# STM32L562 register map
File version: 1.1
Registers are 32-bit, read-write, reset 0x0 unless marked. A register's access mark holds for its fields unless they carry their own. Offsets are from the block's base; [hi:lo] are bit positions; {n}, {i} and the like mark numbered series.

## USB — Universal serial bus full-speed device interface
Base 0x4000D400
Same registers: SEC_USB 0x5000D400
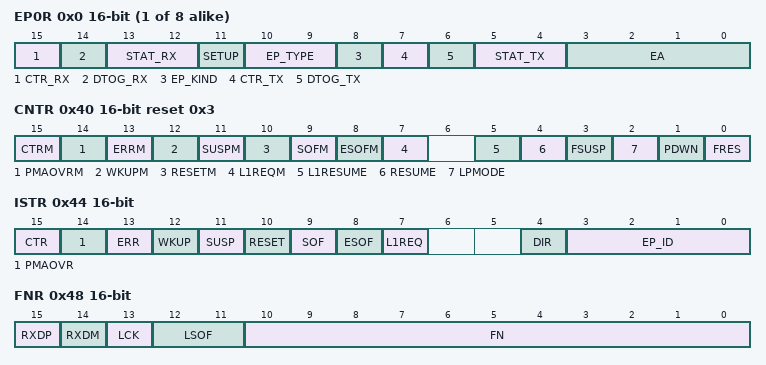
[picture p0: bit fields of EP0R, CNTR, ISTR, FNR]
{0x0+4i} EP{i}R 16-bit (i=0..7) — endpoint {i} register
  [15] CTR_RX — Correct transfer for reception
  [14] DTOG_RX — Data Toggle, for reception transfers
  [13:12] STAT_RX — Status bits, for reception transfers
  [11] SETUP — Setup transaction completed
  [10:9] EP_TYPE — Endpoint type
  [8] EP_KIND — Endpoint kind
  [7] CTR_TX — Correct Transfer for transmission
  [6] DTOG_TX — Data Toggle, for transmission transfers
  [5:4] STAT_TX — Status bits, for transmission transfers
  [3:0] EA — Endpoint address
0x40 CNTR 16-bit reset 0x3 — control register
  [15] CTRM — Correct transfer interrupt mask
  [14] PMAOVRM — Packet memory area over / underrun interrupt mask
  [13] ERRM — Error interrupt mask
  [12] WKUPM — Wakeup interrupt mask
  [11] SUSPM — Suspend mode interrupt mask
  [10] RESETM — USB reset interrupt mask
  [9] SOFM — Start of frame interrupt mask
  [8] ESOFM — Expected start of frame interrupt mask
  [7] L1REQM — LPM L1 state request interrupt mask
  [5] L1RESUME — LPM L1 Resume request
  [4] RESUME — Resume request
  [3] FSUSP — Force suspend
  [2] LPMODE — Low-power mode
  [1] PDWN — Power down
  [0] FRES — Force USB Reset
0x44 ISTR 16-bit access per field — interrupt status register
  [15] CTR ro — Correct transfer
  [14] PMAOVR rw — Packet memory area over / underrun
  [13] ERR rw — Error
  [12] WKUP rw — Wakeup
  [11] SUSP rw — Suspend mode request
  [10] RESET rw — reset request
  [9] SOF rw — start of frame
  [8] ESOF rw — Expected start frame
  [7] L1REQ rw — LPM L1 state request
  [4] DIR ro — Direction of transaction
  [3:0] EP_ID ro — Endpoint Identifier
0x48 FNR 16-bit ro — frame number register
  [15] RXDP — Receive data + line status
  [14] RXDM — Receive data - line status
  [13] LCK — Locked
  [12:11] LSOF — Lost SOF
  [10:0] FN — Frame number
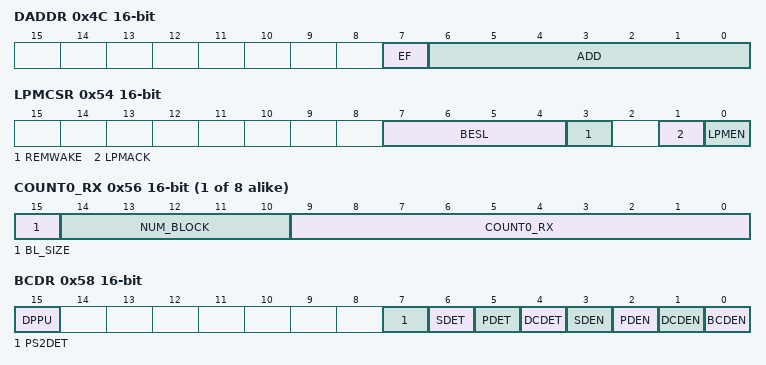
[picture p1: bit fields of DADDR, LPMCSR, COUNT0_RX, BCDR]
0x4C DADDR 16-bit — device address
  [7] EF — Enable function
  [6:0] ADD — Device address
0x50 BTABLE 16-bit — Buffer table address
  [15:3] BTABLE — Buffer table
{0x52+8i} COUNT{i}_TX 16-bit (i=0..7) — Transmission byte count 0
  [9:0] COUNT{i}_TX — Transmission byte count
0x54 LPMCSR 16-bit — LPM control and status register
  [7:4] BESL — BESL value
  [3] REMWAKE — RemoteWake value
  [1] LPMACK — LPM Token acknowledge enable
  [0] LPMEN — LPM support enable
{0x56+8i} COUNT{i}_RX 16-bit access per field (i=0..7) — Reception byte count 0
  [15] BL_SIZE rw — Block size
  [14:10] NUM_BLOCK rw — Number of blocks
  [9:0] COUNT{i}_RX ro — Reception byte count
0x58 BCDR 16-bit — Battery charging detector
  [15] DPPU — DP pull-up control
  [7] PS2DET — DM pull-up detection status
  [6] SDET — Secondary detection (SD) status
  [5] PDET — Primary detection (PD) status
  [4] DCDET — Data contact detection (DCD) status
  [3] SDEN — Secondary detection (SD) mode enable
  [2] PDEN — Primary detection (PD) mode enable
  [1] DCDEN — Data contact detection (DCD) mode enable
  [0] BCDEN — Battery charging detector (BCD) enable
{0x5C+8i} ADDR{i}_RX 16-bit (i=0..7) — Reception buffer address 0
  [15:1] ADDR{i}_RX — Reception buffer address

## LPUART1 — Universal synchronous asynchronous receiver transmitter
Base 0x40008000
Same registers: SEC_LPUART1 0x50008000
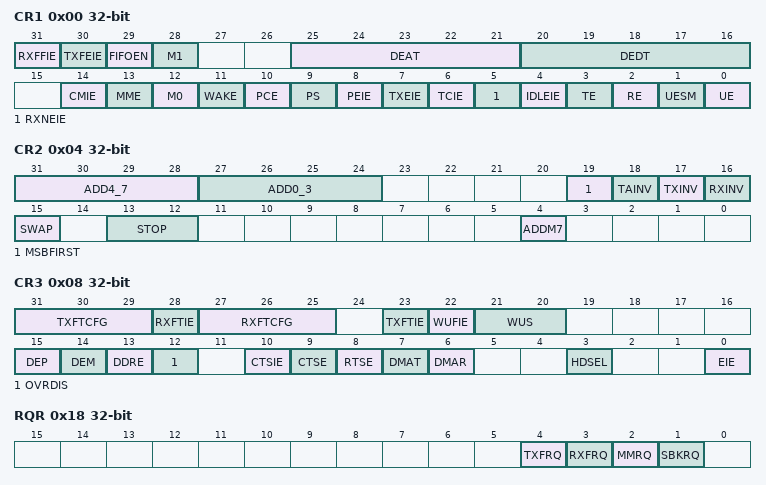
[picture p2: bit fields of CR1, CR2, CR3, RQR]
0x00 CR1 — Control register 1
  [31] RXFFIE
  [30] TXFEIE
  [29] FIFOEN
  [28] M1 — Word length
  [25:21] DEAT
  [20:16] DEDT
  [14] CMIE — Character match interrupt enable
  [13] MME — Mute mode enable
  [12] M0 — Word length
  [11] WAKE — Receiver wakeup method
  [10] PCE — Parity control enable
  [9] PS — Parity selection
  [8] PEIE — PE interrupt enable
  [7] TXEIE — interrupt enable
  [6] TCIE — Transmission complete interrupt enable
  [5] RXNEIE — RXNE interrupt enable
  [4] IDLEIE — IDLE interrupt enable
  [3] TE — Transmitter enable
  [2] RE — Receiver enable
  [1] UESM — USART enable in Stop mode
  [0] UE — USART enable
0x04 CR2 — Control register 2
  [31:28] ADD4_7 — Address of the USART node
  [27:24] ADD0_3 — Address of the USART node
  [19] MSBFIRST — Most significant bit first
  [18] TAINV — Binary data inversion
  [17] TXINV — TX pin active level inversion
  [16] RXINV — RX pin active level inversion
  [15] SWAP — Swap TX/RX pins
  [13:12] STOP — STOP bits
  [4] ADDM7 — 7-bit Address Detection/4-bit Address Detection
0x08 CR3 — Control register 3
  [31:29] TXFTCFG
  [28] RXFTIE
  [27:25] RXFTCFG
  [23] TXFTIE
  [22] WUFIE — Wakeup from Stop mode interrupt enable
  [21:20] WUS — Wakeup from Stop mode interrupt flag selection
  [15] DEP — Driver enable polarity selection
  [14] DEM — Driver enable mode
  [13] DDRE — DMA Disable on Reception Error
  [12] OVRDIS — Overrun Disable
  [10] CTSIE — CTS interrupt enable
  [9] CTSE — CTS enable
  [8] RTSE — RTS enable
  [7] DMAT — DMA enable transmitter
  [6] DMAR — DMA enable receiver
  [3] HDSEL — Half-duplex selection
  [0] EIE — Error interrupt enable
0x0C BRR — Baud rate register
  [19:0] BRR
0x18 RQR wo — Request register
  [4] TXFRQ
  [3] RXFRQ — Receive data flush request
  [2] MMRQ — Mute mode request
  [1] SBKRQ — Send break request
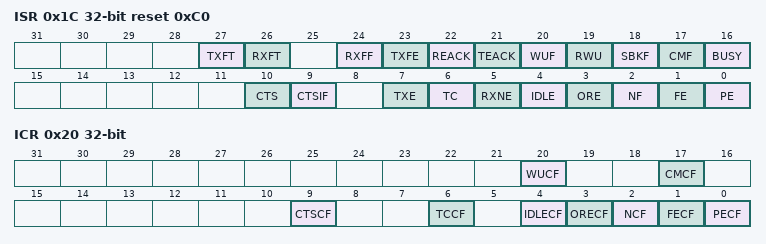
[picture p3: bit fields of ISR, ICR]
0x1C ISR ro reset 0xC0 — Interrupt & status register
  [27] TXFT, [26] RXFT, [24] RXFF, [23] TXFE, [22] REACK, [21] TEACK, [20] WUF, [19] RWU, [18] SBKF, [17] CMF, [16] BUSY, [10] CTS, [9] CTSIF, [7] TXE, [6] TC, [5] RXNE, [4] IDLE, [3] ORE, [2] NF, [1] FE, [0] PE
0x20 ICR wo — Interrupt flag clear register
  [20] WUCF — Wakeup from Stop mode clear flag
  [17] CMCF — Character match clear flag
  [9] CTSCF — CTS clear flag
  [6] TCCF — Transmission complete clear flag
  [4] IDLECF — Idle line detected clear flag
  [3] ORECF — Overrun error clear flag
  [2] NCF — Noise detected clear flag
  [1] FECF — Framing error clear flag
  [0] PECF — Parity error clear flag
0x24 RDR ro — Receive data register
  [8:0] RDR — Receive data value
0x28 TDR — Transmit data register
  [8:0] TDR — Transmit data value
0x2C PRESC
  [3:0] PRESCALER
